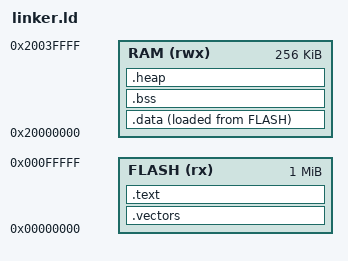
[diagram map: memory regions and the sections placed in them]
ENTRY(Reset_Handler)

MEMORY
{
    FLASH (rx)  : ORIGIN = 0x00000000, LENGTH = 1M
    RAM   (rwx) : ORIGIN = 0x20000000, LENGTH = 256K
}

SECTIONS
{
    .vectors :
    {
        KEEP(*(.vectors))
    } > FLASH

    .text :
    {
        *(.text*)
        *(.rodata*)
    } > FLASH

    .data :
    {
        _sdata = .;
        *(.data*)
        _edata = .;
    } > RAM AT > FLASH

    .bss :
    {
        __bss_start__ = .;
        *(.bss*)
        *(COMMON)
        __bss_end__ = .;
    } > RAM

    .heap :
    {
        . = ALIGN(8);
        end = .;
        . = . + 0x1000;
        . = ALIGN(8);
    } > RAM
}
